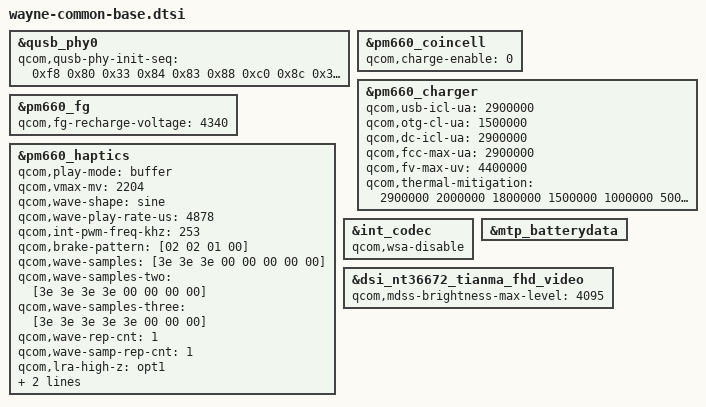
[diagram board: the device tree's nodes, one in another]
/* Copyright (c) 2019, The Linux Foundation. All rights reserved.
 *
 * This program is free software; you can redistribute it and/or modify
 * it under the terms of the GNU General Public License version 2 and
 * only version 2 as published by the Free Software Foundation.
 *
 * This program is distributed in the hope that it will be useful,
 * but WITHOUT ANY WARRANTY; without even the implied warranty of
 * MERCHANTABILITY or FITNESS FOR A PARTICULAR PURPOSE.  See the
 * GNU General Public License for more details.
 */
#include "wayne-camera-sensor-mtp.dtsi"
#include "sdm660-novatek-i2c_d2s.dtsi"

/* sdm660-common.dtsi diff wayne - whyred/tulip */
&qusb_phy0 {
	qcom,qusb-phy-init-seq = <0xf8 0x80
				0x33 0x84
				0x83 0x88
				0xc0 0x8c
				0x30 0x08
				0x79 0x0c
				0x21 0x10
				0x14 0x9c
				0x9f 0x1c
				0x00 0x18>;
};

/* msm-pm660.dtsi wayne specific diff */
&pm660_coincell {
	qcom,charge-enable = <0>;
};

&pm660_charger {
	qcom,usb-icl-ua = <2900000>;
	qcom,otg-cl-ua = <1500000>;
	qcom,dc-icl-ua = <2900000>;
	qcom,fcc-max-ua = <2900000>;
	qcom,fv-max-uv  = <4400000>;
	qcom,thermal-mitigation
			= <2900000 2000000 1800000 1500000 1000000 500000 100000>;
};

&pm660_fg {
	qcom,fg-recharge-voltage = <4340>;
};

&pm660_haptics {
	/delete-property/ qcom,correct-lra-drive-freq;
	qcom,play-mode = "buffer";
	qcom,vmax-mv = <2204>;
	qcom,wave-shape = "sine";
	qcom,wave-play-rate-us = <4878>;
	qcom,int-pwm-freq-khz = <253>;
	qcom,brake-pattern = [02 02 01 00];
	qcom,wave-samples = [3e 3e 3e 00 00 00 00 00];
	qcom,wave-samples-two = [3e 3e 3e 3e 00 00 00 00];
	qcom,wave-samples-three = [3e 3e 3e 3e 3e 00 00 00];
	qcom,wave-rep-cnt = <1>;
	qcom,wave-samp-rep-cnt = <1>;
	qcom,lra-high-z = "opt1";
	qcom,lra-auto-res-mode = "none";
	qcom,lra-hw-auto-resonance;
};


/* msm-audio.dtsi wayne specific diff */
&int_codec {
	qcom,wsa-disable;
	/delete-property/ qcom,msm-micbias2-ext-cap;
};

/* sdm660-mtp.dtsi wayne specific diff */
&mtp_batterydata {
	#include "fg-gen3-batterydata-l8866sun-3000mah.dtsi"
	#include "fg-gen3-batterydata-l8866cos-3000mah.dtsi"
	#include "fg-gen3-batterydata-l8866default-3000mah.dtsi"
};

&dsi_nt36672_tianma_fhd_video {
	qcom,mdss-brightness-max-level = <4095>;
};
